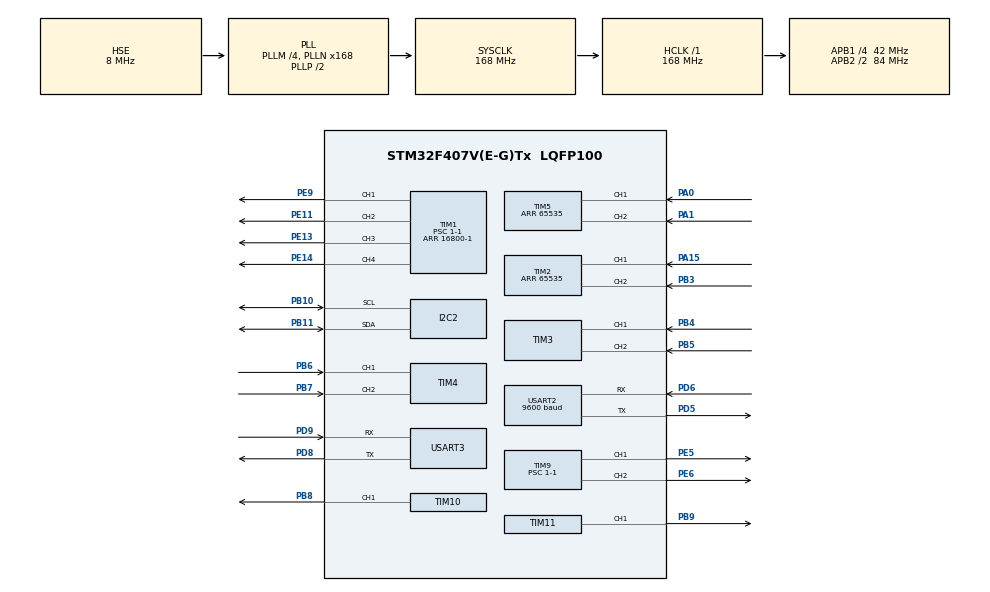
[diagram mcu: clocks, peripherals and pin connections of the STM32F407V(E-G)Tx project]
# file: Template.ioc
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Dma.Request0=USART3_RX
Dma.Request1=USART3_TX
Dma.Request2=USART2_RX
Dma.USART2_RX.2.Direction=DMA_PERIPH_TO_MEMORY
Dma.USART2_RX.2.FIFOMode=DMA_FIFOMODE_DISABLE
Dma.USART2_RX.2.Instance=DMA1_Stream5
Dma.USART2_RX.2.MemDataAlignment=DMA_MDATAALIGN_BYTE
Dma.USART2_RX.2.MemInc=DMA_MINC_ENABLE
Dma.USART2_RX.2.Mode=DMA_CIRCULAR
Dma.USART2_RX.2.PeriphDataAlignment=DMA_PDATAALIGN_BYTE
Dma.USART2_RX.2.PeriphInc=DMA_PINC_DISABLE
Dma.USART2_RX.2.Priority=DMA_PRIORITY_VERY_HIGH
Dma.USART3_RX.0.Direction=DMA_PERIPH_TO_MEMORY
Dma.USART3_RX.0.FIFOMode=DMA_FIFOMODE_DISABLE
Dma.USART3_RX.0.Instance=DMA1_Stream1
Dma.USART3_RX.0.MemDataAlignment=DMA_MDATAALIGN_BYTE
Dma.USART3_RX.0.MemInc=DMA_MINC_ENABLE
Dma.USART3_RX.0.Mode=DMA_CIRCULAR
Dma.USART3_RX.0.PeriphDataAlignment=DMA_PDATAALIGN_BYTE
Dma.USART3_RX.0.PeriphInc=DMA_PINC_DISABLE
Dma.USART3_RX.0.Priority=DMA_PRIORITY_VERY_HIGH
Dma.USART3_TX.1.Direction=DMA_MEMORY_TO_PERIPH
Dma.USART3_TX.1.FIFOMode=DMA_FIFOMODE_DISABLE
Dma.USART3_TX.1.Instance=DMA1_Stream3
Dma.USART3_TX.1.MemDataAlignment=DMA_MDATAALIGN_BYTE
Dma.USART3_TX.1.MemInc=DMA_MINC_ENABLE
Dma.USART3_TX.1.Mode=DMA_NORMAL
Dma.USART3_TX.1.PeriphDataAlignment=DMA_PDATAALIGN_BYTE
Dma.USART3_TX.1.PeriphInc=DMA_PINC_DISABLE
Dma.USART3_TX.1.Priority=DMA_PRIORITY_VERY_HIGH
FREERTOS.BinarySemaphores01=MOTOR_ROS2_Semap,Dynamic,NULL,Depleted
FREERTOS.INCLUDE_vTaskDelayUntil=1
FREERTOS.Tasks01=CHASSIS_TASK,24,128,chassis_task,As weak,NULL,Dynamic,NULL,NULL;IMU_TASK,24,128,imu_task,As weak,NULL,Dynamic,NULL,NULL;ROS2_UART_TASK,24,128,ros2_uart_task,As weak,NULL,Dynamic,NULL,NULL
I2C2.I2C_Mode=I2C_Fast
Mcu.Family=STM32F4
Mcu.Name=STM32F407V(E-G)Tx
Mcu.Package=LQFP100
NVIC.DMA1_Stream1_IRQn=true\:5\:0\:false\:false\:true\:true\:false\:true\:true
NVIC.DMA1_Stream3_IRQn=true\:5\:0\:false\:false\:true\:true\:false\:true\:true
NVIC.DMA1_Stream5_IRQn=true\:5\:0\:false\:false\:true\:true\:false\:true\:true
NVIC.I2C2_ER_IRQn=true\:5\:0\:false\:false\:true\:true\:true\:true\:true
NVIC.I2C2_EV_IRQn=true\:5\:0\:false\:false\:true\:true\:true\:true\:true
NVIC.PriorityGroup=NVIC_PRIORITYGROUP_4
NVIC.TIM2_IRQn=true\:5\:0\:false\:false\:true\:true\:true\:true\:true
NVIC.TIM3_IRQn=true\:5\:0\:false\:false\:true\:true\:true\:true\:true
NVIC.TIM4_IRQn=true\:5\:0\:false\:false\:true\:true\:true\:true\:true
NVIC.TIM5_IRQn=true\:5\:0\:false\:false\:true\:true\:true\:true\:true
NVIC.TIM6_DAC_IRQn=true\:5\:0\:false\:false\:true\:true\:true\:true\:true
NVIC.TIM7_IRQn=true\:15\:0\:false\:false\:true\:false\:false\:true\:true
NVIC.TimeBase=TIM7_IRQn
NVIC.TimeBaseIP=TIM7
NVIC.USART2_IRQn=true\:5\:0\:false\:false\:true\:true\:true\:true\:true
NVIC.USART3_IRQn=true\:5\:0\:false\:false\:true\:true\:true\:true\:true
PA0-WKUP.Signal=S_TIM5_CH1
PA1.Signal=S_TIM5_CH2
PA13.Mode=Serial_Wire
PA13.Signal=SYS_JTMS-SWDIO
PA14.Mode=Serial_Wire
PA14.Signal=SYS_JTCK-SWCLK
PA15.Signal=S_TIM2_CH1_ETR
PB10.Mode=I2C
PB10.Signal=I2C2_SCL
PB11.Mode=I2C
PB11.Signal=I2C2_SDA
PB3.Signal=S_TIM2_CH2
PB4.Signal=S_TIM3_CH1
PB5.Signal=S_TIM3_CH2
PB6.Signal=S_TIM4_CH1
PB7.Signal=S_TIM4_CH2
PB8.Signal=S_TIM10_CH1
PB9.Signal=S_TIM11_CH1
PD5.Mode=Asynchronous
PD5.Signal=USART2_TX
PD6.Mode=Asynchronous
PD6.Signal=USART2_RX
PD8.Mode=Asynchronous
PD8.Signal=USART3_TX
PD9.Mode=Asynchronous
PD9.Signal=USART3_RX
PE11.Signal=S_TIM1_CH2
PE13.Signal=S_TIM1_CH3
PE14.Signal=S_TIM1_CH4
PE5.Signal=S_TIM9_CH1
PE6.Signal=S_TIM9_CH2
PE9.Signal=S_TIM1_CH1
PH0-OSC_IN.Mode=HSE-External-Oscillator
PH0-OSC_IN.Signal=RCC_OSC_IN
PH1-OSC_OUT.Mode=HSE-External-Oscillator
PH1-OSC_OUT.Signal=RCC_OSC_OUT
ProjectManager.HeapSize=0x200
ProjectManager.StackSize=0x400
ProjectManager.TargetToolchain=MDK-ARM V5.32
RCC.48MHZClocksFreq_Value=84000000
RCC.AHBFreq_Value=168000000
RCC.APB1CLKDivider=RCC_HCLK_DIV4
RCC.APB1Freq_Value=42000000
RCC.APB1TimFreq_Value=84000000
RCC.APB2CLKDivider=RCC_HCLK_DIV2
RCC.APB2Freq_Value=84000000
RCC.APB2TimFreq_Value=168000000
RCC.CortexFreq_Value=168000000
RCC.HCLKFreq_Value=168000000
RCC.HSE_VALUE=8000000
RCC.HSI_VALUE=16000000
RCC.LSE_VALUE=32768
RCC.PLLM=4
RCC.PLLN=168
RCC.PLLSourceVirtual=RCC_PLLSOURCE_HSE
RCC.SYSCLKFreq_VALUE=168000000
RCC.SYSCLKSource=RCC_SYSCLKSOURCE_PLLCLK
RCC.VCOOutputFreq_Value=336000000
SH.S_TIM10_CH1.0=TIM10_CH1,PWM Generation1 CH1
SH.S_TIM11_CH1.0=TIM11_CH1,PWM Generation1 CH1
SH.S_TIM1_CH1.0=TIM1_CH1,PWM Generation1 CH1
SH.S_TIM1_CH2.0=TIM1_CH2,PWM Generation2 CH2
SH.S_TIM1_CH3.0=TIM1_CH3,PWM Generation3 CH3
SH.S_TIM1_CH4.0=TIM1_CH4,PWM Generation4 CH4
SH.S_TIM2_CH1_ETR.0=TIM2_CH1,Encoder_Interface
SH.S_TIM2_CH2.0=TIM2_CH2,Encoder_Interface
SH.S_TIM3_CH1.0=TIM3_CH1,Encoder_Interface
SH.S_TIM3_CH2.0=TIM3_CH2,Encoder_Interface
SH.S_TIM4_CH1.0=TIM4_CH1,Encoder_Interface
SH.S_TIM4_CH2.0=TIM4_CH2,Encoder_Interface
SH.S_TIM5_CH1.0=TIM5_CH1,Encoder_Interface
SH.S_TIM5_CH2.0=TIM5_CH2,Encoder_Interface
SH.S_TIM9_CH1.0=TIM9_CH1,PWM Generation1 CH1
SH.S_TIM9_CH2.0=TIM9_CH2,PWM Generation2 CH2
STMicroelectronics.X-CUBE-ALGOBUILD.1.4.0.LibraryCcDSPOoLibraryJjDSPOoLibrary=true
TIM1.Channel-PWM\ Generation1\ CH1=TIM_CHANNEL_1
TIM1.Channel-PWM\ Generation2\ CH2=TIM_CHANNEL_2
TIM1.Channel-PWM\ Generation3\ CH3=TIM_CHANNEL_3
TIM1.Channel-PWM\ Generation4\ CH4=TIM_CHANNEL_4
TIM1.Period=16800-1
TIM1.Prescaler=1-1
TIM10.Channel=TIM_CHANNEL_1
TIM10.Period=16800-1
TIM10.Prescaler=1-1
TIM11.Channel=TIM_CHANNEL_1
TIM11.Period=16800-1
TIM11.Prescaler=1-1
TIM2.EncoderMode=TIM_ENCODERMODE_TI12
TIM2.IC1Filter=10
TIM2.IC2Filter=10
TIM2.Period=65535
TIM3.EncoderMode=TIM_ENCODERMODE_TI12
TIM3.IC1Filter=10
TIM3.IC2Filter=10
TIM4.EncoderMode=TIM_ENCODERMODE_TI12
TIM4.IC1Filter=10
TIM4.IC2Filter=10
TIM5.EncoderMode=TIM_ENCODERMODE_TI12
TIM5.IC1Filter=10
TIM5.IC2Filter=10
TIM5.Period=65535
TIM6.Period=1000-1
TIM6.Prescaler=84-1
TIM9.Channel-PWM\ Generation1\ CH1=TIM_CHANNEL_1
TIM9.Channel-PWM\ Generation2\ CH2=TIM_CHANNEL_2
TIM9.Period=16800-1
TIM9.Prescaler=1-1
USART2.BaudRate=9600
USART2.Parity=PARITY_NONE
USART2.VirtualMode=VM_ASYNC
USART3.VirtualMode=VM_ASYNC
VP_FREERTOS_VS_CMSIS_V2.Mode=CMSIS_V2
VP_STMicroelectronics.X-CUBE-ALGOBUILD_VS_DSPOoLibraryJjLibrary_1.4.0_1.4.0.Mode=DSPOoLibraryJjLibrary
VP_SYS_VS_tim7.Mode=TIM7
VP_TIM10_VS_ClockSourceINT.Mode=Enable_Timer
VP_TIM11_VS_ClockSourceINT.Mode=Enable_Timer
VP_TIM1_VS_ClockSourceINT.Mode=Internal
VP_TIM6_VS_ClockSourceINT.Mode=Enable_Timer
VP_TIM9_VS_ClockSourceINT.Mode=Internal
board=custom

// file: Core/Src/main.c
/* USER CODE BEGIN Header */
/**
  ******************************************************************************
  * @file           : main.c
  * @brief          : Main program body
  ******************************************************************************
  * @attention
  *
  * Copyright (c) 2024 STMicroelectronics.
  * All rights reserved.
  *
  * This software is licensed under terms that can be found in the LICENSE file
  * in the root directory of this software component.
  * If no LICENSE file comes with this software, it is provided AS-IS.
  *
  ******************************************************************************
  */
/* USER CODE END Header */
#include "main.h"
#include "cmsis_os.h"
#include "dma.h"
#include "i2c.h"
#include "tim.h"
#include "usart.h"
#include "gpio.h"

/* USER CODE BEGIN Includes */
#include "startup_main.h"
/* USER CODE END Includes */

void SystemClock_Config(void);
void MX_FREERTOS_Init(void);

int main(void)
{

  /* MCU Configuration--------------------------------------------------------*/

  /* Reset of all peripherals, Initializes the Flash interface and the Systick. */
  HAL_Init();

  /* Configure the system clock */
  SystemClock_Config();

  /* Initialize all configured peripherals */
  MX_GPIO_Init();
  MX_DMA_Init();
  MX_TIM2_Init();
  MX_TIM6_Init();
  MX_TIM10_Init();
  MX_TIM11_Init();
  MX_TIM1_Init();
  MX_TIM3_Init();
  MX_TIM4_Init();
  MX_TIM5_Init();
  MX_TIM9_Init();
  MX_USART2_UART_Init();
  MX_I2C2_Init();
  MX_USART3_UART_Init();
  /* USER CODE BEGIN 2 */
  startup_main();
  /* USER CODE END 2 */

  /* Init scheduler */
  osKernelInitialize();

  /* Call init function for freertos objects (in cmsis_os2.c) */
  MX_FREERTOS_Init();

  /* Start scheduler */
  osKernelStart();

  /* We should never get here as control is now taken by the scheduler */

  /* Infinite loop */
  while (1)
  {

  }
}

void SystemClock_Config(void)
{
  RCC_OscInitTypeDef RCC_OscInitStruct = {0};
  RCC_ClkInitTypeDef RCC_ClkInitStruct = {0};

  /** Configure the main internal regulator output voltage
  */
  __HAL_RCC_PWR_CLK_ENABLE();
  __HAL_PWR_VOLTAGESCALING_CONFIG(PWR_REGULATOR_VOLTAGE_SCALE1);

  /** Initializes the RCC Oscillators according to the specified parameters
  * in the RCC_OscInitTypeDef structure.
  */
  RCC_OscInitStruct.OscillatorType = RCC_OSCILLATORTYPE_HSE;
  RCC_OscInitStruct.HSEState = RCC_HSE_ON;
  RCC_OscInitStruct.PLL.PLLState = RCC_PLL_ON;
  RCC_OscInitStruct.PLL.PLLSource = RCC_PLLSOURCE_HSE;
  RCC_OscInitStruct.PLL.PLLM = 4;
  RCC_OscInitStruct.PLL.PLLN = 168;
  RCC_OscInitStruct.PLL.PLLP = RCC_PLLP_DIV2;
  RCC_OscInitStruct.PLL.PLLQ = 4;
  if (HAL_RCC_OscConfig(&RCC_OscInitStruct) != HAL_OK)
  {
    Error_Handler();
  }

  /** Initializes the CPU, AHB and APB buses clocks
  */
  RCC_ClkInitStruct.ClockType = RCC_CLOCKTYPE_HCLK|RCC_CLOCKTYPE_SYSCLK
                              |RCC_CLOCKTYPE_PCLK1|RCC_CLOCKTYPE_PCLK2;
  RCC_ClkInitStruct.SYSCLKSource = RCC_SYSCLKSOURCE_PLLCLK;
  RCC_ClkInitStruct.AHBCLKDivider = RCC_SYSCLK_DIV1;
  RCC_ClkInitStruct.APB1CLKDivider = RCC_HCLK_DIV4;
  RCC_ClkInitStruct.APB2CLKDivider = RCC_HCLK_DIV2;

  if (HAL_RCC_ClockConfig(&RCC_ClkInitStruct, FLASH_LATENCY_5) != HAL_OK)
  {
    Error_Handler();
  }
}

//void HAL_TIM_PeriodElapsedCallback(TIM_HandleTypeDef *htim)
//{
//  /* USER CODE BEGIN Callback 0 */

//  /* USER CODE END Callback 0 */
//  if (htim->Instance == TIM7) {
//    HAL_IncTick();
//  }
//  /* USER CODE BEGIN Callback 1 */

//  /* USER CODE END Callback 1 */
//}

void Error_Handler(void)
{
  __disable_irq();
  while (1)
  {
  }
}

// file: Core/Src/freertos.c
/* USER CODE BEGIN Header */
/**
  ******************************************************************************
  * File Name          : freertos.c
  * Description        : Code for freertos applications
  ******************************************************************************
  * @attention
  *
  * Copyright (c) 2024 STMicroelectronics.
  * All rights reserved.
  *
  * This software is licensed under terms that can be found in the LICENSE file
  * in the root directory of this software component.
  * If no LICENSE file comes with this software, it is provided AS-IS.
  *
  ******************************************************************************
  */
/* USER CODE END Header */

#include "FreeRTOS.h"
#include "task.h"
#include "main.h"
#include "cmsis_os.h"

/* Definitions for CHASSIS_TASK */
osThreadId_t CHASSIS_TASKHandle;
const osThreadAttr_t CHASSIS_TASK_attributes = {
  .name = "CHASSIS_TASK",
  .stack_size = 128 * 4,
  .priority = (osPriority_t) osPriorityNormal,
};
/* Definitions for IMU_TASK */
osThreadId_t IMU_TASKHandle;
const osThreadAttr_t IMU_TASK_attributes = {
  .name = "IMU_TASK",
  .stack_size = 128 * 4,
  .priority = (osPriority_t) osPriorityNormal,
};
/* Definitions for ROS2_UART_TASK */
osThreadId_t ROS2_UART_TASKHandle;
const osThreadAttr_t ROS2_UART_TASK_attributes = {
  .name = "ROS2_UART_TASK",
  .stack_size = 128 * 4,
  .priority = (osPriority_t) osPriorityNormal,
};
/* Definitions for MOTOR_ROS2_Semap */
osSemaphoreId_t MOTOR_ROS2_SemapHandle;
const osSemaphoreAttr_t MOTOR_ROS2_Semap_attributes = {
  .name = "MOTOR_ROS2_Semap"
};

void chassis_task(void *argument);
void imu_task(void *argument);
void ros2_uart_task(void *argument);

void MX_FREERTOS_Init(void); /* (MISRA C 2004 rule 8.1) */

void MX_FREERTOS_Init(void) {

  /* Create the semaphores(s) */
  /* creation of MOTOR_ROS2_Semap */
  MOTOR_ROS2_SemapHandle = osSemaphoreNew(1, 0, &MOTOR_ROS2_Semap_attributes);

  /* Create the thread(s) */
  /* creation of CHASSIS_TASK */
  CHASSIS_TASKHandle = osThreadNew(chassis_task, NULL, &CHASSIS_TASK_attributes);

  /* creation of IMU_TASK */
  IMU_TASKHandle = osThreadNew(imu_task, NULL, &IMU_TASK_attributes);

  /* creation of ROS2_UART_TASK */
  ROS2_UART_TASKHandle = osThreadNew(ros2_uart_task, NULL, &ROS2_UART_TASK_attributes);

}

__weak void chassis_task(void *argument)
{
  for(;;)
  {
    osDelay(1);
  }
}

__weak void imu_task(void *argument)
{
  for(;;)
  {
    osDelay(1);
  }
}

__weak void ros2_uart_task(void *argument)
{
  for(;;)
  {
    osDelay(1);
  }
}
